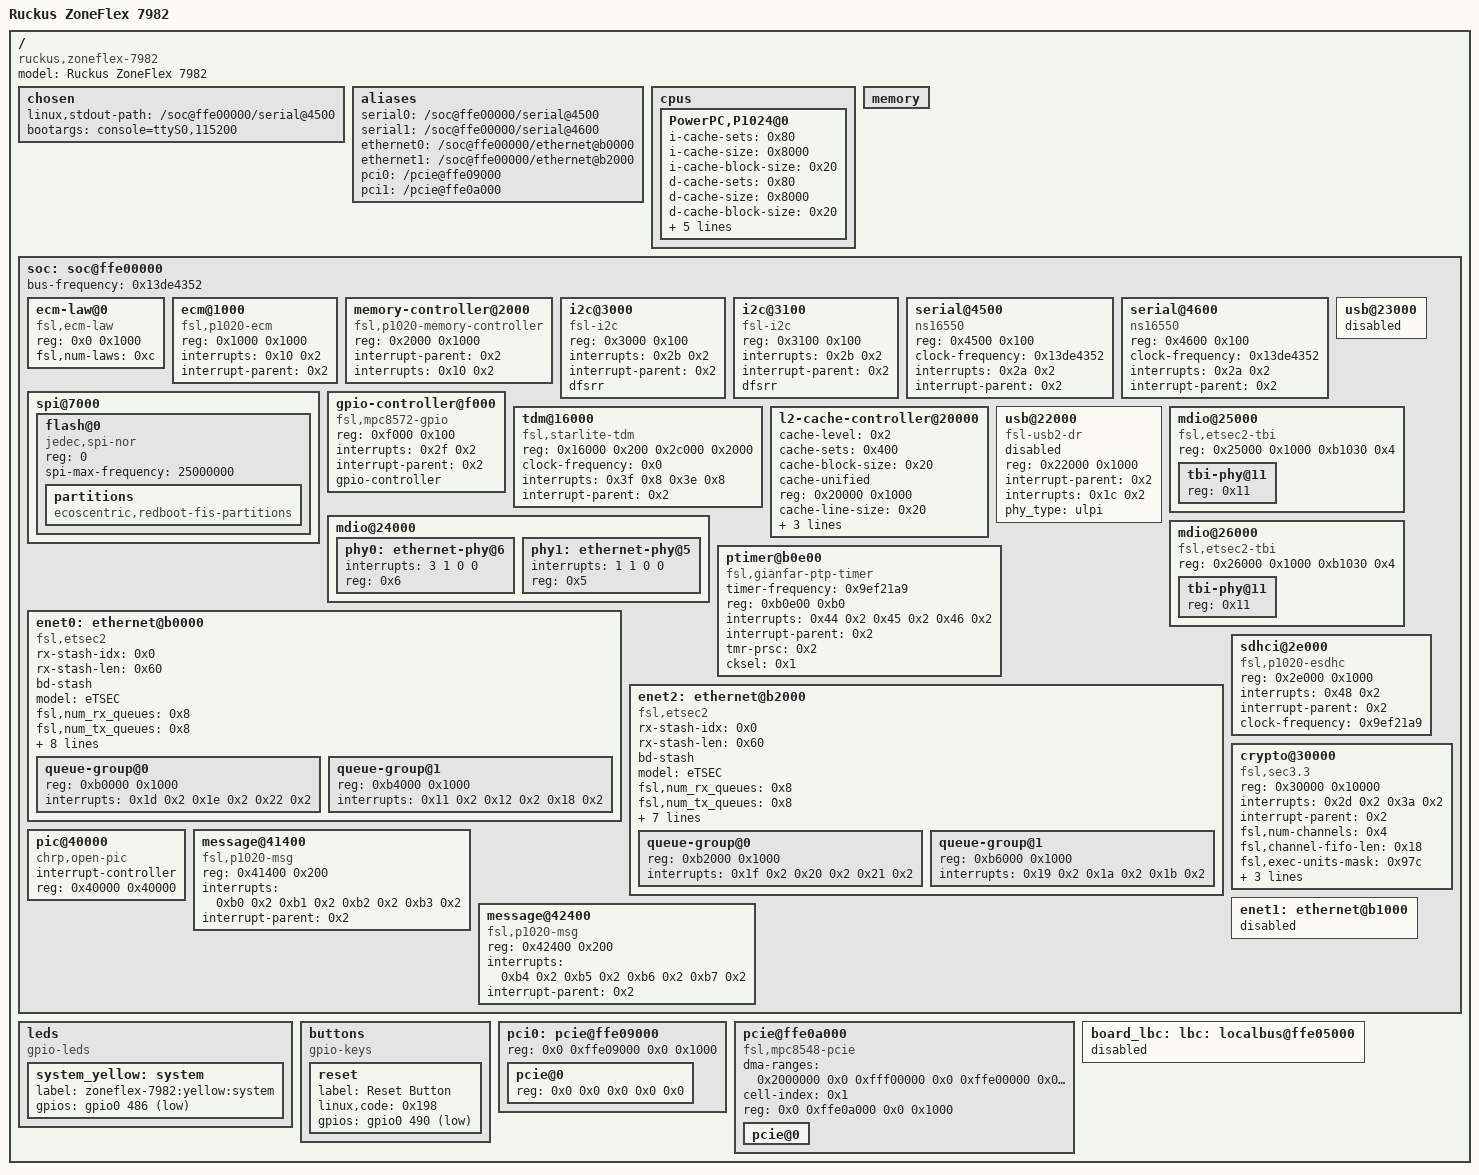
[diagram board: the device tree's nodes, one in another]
/dts-v1/;

/memreserve/	0x0000000007f00000 0x0000000000100000;
/memreserve/	0x0000000000ff6000 0x0000000000007000;
/ {
	model = "Ruckus ZoneFlex 7982";
	compatible = "ruckus,zoneflex-7982";
	#address-cells = <0x2>;
	#size-cells = <0x2>;

	chosen {
		linux,stdout-path = "/soc@ffe00000/serial@4500";
		bootargs = "console=ttyS0,115200";
	};

	aliases {
		serial0 = "/soc@ffe00000/serial@4500";
		serial1 = "/soc@ffe00000/serial@4600";
		ethernet0 = "/soc@ffe00000/ethernet@b0000";
		ethernet1 = "/soc@ffe00000/ethernet@b2000";
		pci0 = "/pcie@ffe09000";
		pci1 = "/pcie@ffe0a000";
	};

	cpus {
		#address-cells = <0x1>;
		#size-cells = <0x0>;

		PowerPC,P1024@0 {
			i-cache-sets = <0x80>;
			i-cache-size = <0x8000>;
			i-cache-block-size = <0x20>;
			d-cache-sets = <0x80>;
			d-cache-size = <0x8000>;
			d-cache-block-size = <0x20>;
			clock-frequency = <0x27bc86a4>;
			bus-frequency = <0x13de4352>;
			timebase-frequency = <0x27bc86a>;
			device_type = "cpu";
			reg = <0x0>;
			next-level-cache = <0x1>;
		};
	};

	memory {
		device_type = "memory";
	};

	soc: soc@ffe00000 {
		ranges = <0x0 0x0 0xffe00000 0x100000>;
		bus-frequency = <0x13de4352>;

		ecm-law@0 {
			compatible = "fsl,ecm-law";
			reg = <0x0 0x1000>;
			fsl,num-laws = <0xc>;
		};

		ecm@1000 {
			compatible = "fsl,p1020-ecm", "fsl,ecm";
			reg = <0x1000 0x1000>;
			interrupts = <0x10 0x2>;
			interrupt-parent = <0x2>;
		};

		memory-controller@2000 {
			compatible = "fsl,p1020-memory-controller";
			reg = <0x2000 0x1000>;
			interrupt-parent = <0x2>;
			interrupts = <0x10 0x2>;
		};

		i2c@3000 {
			#address-cells = <0x1>;
			#size-cells = <0x0>;
			compatible = "fsl-i2c";
			reg = <0x3000 0x100>;
			interrupts = <0x2b 0x2>;
			interrupt-parent = <0x2>;
			dfsrr;
		};

		i2c@3100 {
			#address-cells = <0x1>;
			#size-cells = <0x0>;
			compatible = "fsl-i2c";
			reg = <0x3100 0x100>;
			interrupts = <0x2b 0x2>;
			interrupt-parent = <0x2>;
			dfsrr;
		};

		serial@4500 {
			device_type = "serial";
			compatible = "ns16550";
			reg = <0x4500 0x100>;
			clock-frequency = <0x13de4352>;
			interrupts = <0x2a 0x2>;
			interrupt-parent = <0x2>;
		};

		serial@4600 {
			device_type = "serial";
			compatible = "ns16550";
			reg = <0x4600 0x100>;
			clock-frequency = <0x13de4352>;
			interrupts = <0x2a 0x2>;
			interrupt-parent = <0x2>;
		};

		spi@7000 {
			flash@0 {
				/* test with 40 mhz */
				compatible = "jedec,spi-nor";
				reg = <0>;
				spi-max-frequency = <25000000>;

				partitions {
					compatible = "ecoscentric,redboot-fis-partitions";
				};
			};
		};

		gpio-controller@f000 {
			#gpio-cells = <0x2>;
			compatible = "fsl,mpc8572-gpio";
			reg = <0xf000 0x100>;
			interrupts = <0x2f 0x2>;
			interrupt-parent = <0x2>;
			gpio-controller;
		};

		tdm@16000 {
			compatible = "fsl,starlite-tdm";
			reg = <0x16000 0x200 0x2c000 0x2000>;
			clock-frequency = <0x0>;
			interrupts = <0x3f 0x8 0x3e 0x8>;
			interrupt-parent = <0x2>;
		};

		l2-cache-controller@20000 {
			cache-level = <0x2>;
			cache-sets = <0x400>;
			cache-block-size = <0x20>;
			cache-unified;
			compatible = [66 73 6c 2c 70 31 30 31 31 2d 6c 32 2d 63 61 63 68 65 2d 63 6f 6e 74 72 6f 6c 6c 65 72 00 63 61 63 68 65 00 07 e7];
			reg = <0x20000 0x1000>;
			cache-line-size = <0x20>;
			cache-size = <0x40000>;
			interrupt-parent = <0x2>;
			interrupts = <0x10 0x2>;
			linux,phandle = <0x1>;
		};

		usb@22000 {
			status = "disabled";
		};

		usb@23000 {
			status = "disabled";
		};

		mdio@24000 {
			phy0: ethernet-phy@6 {
				interrupts = <3 1 0 0>;
				reg = <0x6>;
			};

			phy1: ethernet-phy@5 {
				/* todo check interupts. oem use cells: */
				interrupts = <1 1 0 0>;
				reg = <0x5>;
			};
		};

		mdio@25000 {
			#address-cells = <0x1>;
			#size-cells = <0x0>;
			compatible = "fsl,etsec2-tbi";
			reg = <0x25000 0x1000 0xb1030 0x4>;

			tbi-phy@11 {
				reg = <0x11>;
				device_type = "tbi-phy";
			};
		};

		mdio@26000 {
			#address-cells = <0x1>;
			#size-cells = <0x0>;
			compatible = "fsl,etsec2-tbi";
			reg = <0x26000 0x1000 0xb1030 0x4>;

			tbi-phy@11 {
				reg = <0x11>;
				device_type = "tbi-phy";
			};
		};

		ptimer@b0e00 {
			timer-frequency = <0x9ef21a9>;
			compatible = "fsl,gianfar-ptp-timer";
			reg = <0xb0e00 0xb0>;
			interrupts = <0x44 0x2 0x45 0x2 0x46 0x2>;
			interrupt-parent = <0x2>;
			tmr-prsc = <0x2>;
			cksel = <0x1>;
			linux,phandle = <0x4>;
		};

		ethernet@b0000 {
			rx-stash-idx = <0x0>;
			rx-stash-len = <0x60>;
			bd-stash;
			#address-cells = <0x1>;
			#size-cells = <0x1>;
			device_type = "network";
			model = "eTSEC";
			compatible = "fsl,etsec2";
			fsl,num_rx_queues = <0x8>;
			fsl,num_tx_queues = <0x8>;
			local-mac-address = [00 19 77 08 10 00];
			interrupt-parent = <0x2>;
			fixed-link = <0x1 0x1 0x3e8 0x0 0x0>;
			phy-handle = <0x3>;
			phy-connection-type = "rgmii-id";
			ptimer-handle = <0x4>;
			fsl,magic-packet;
			clk-handle = <0x5>;

			queue-group@0 {
				#address-cells = <0x1>;
				#size-cells = <0x1>;
				reg = <0xb0000 0x1000>;
				interrupts = <0x1d 0x2 0x1e 0x2 0x22 0x2>;
			};

			queue-group@1 {
				#address-cells = <0x1>;
				#size-cells = <0x1>;
				reg = <0xb4000 0x1000>;
				interrupts = <0x11 0x2 0x12 0x2 0x18 0x2>;
			};
		};

		ethernet@b2000 {
			rx-stash-idx = <0x0>;
			rx-stash-len = <0x60>;
			bd-stash;
			#address-cells = <0x1>;
			#size-cells = <0x1>;
			device_type = "network";
			model = "eTSEC";
			compatible = "fsl,etsec2";
			fsl,num_rx_queues = <0x8>;
			fsl,num_tx_queues = <0x8>;
			local-mac-address = [00 19 77 08 10 01];
			interrupt-parent = <0x2>;
			phy-handle = <0x6>;
			phy-connection-type = "rgmii-id";
			ptimer-handle = <0x4>;
			fsl,magic-packet;
			clk-handle = <0x7>;

			queue-group@0 {
				#address-cells = <0x1>;
				#size-cells = <0x1>;
				reg = <0xb2000 0x1000>;
				interrupts = <0x1f 0x2 0x20 0x2 0x21 0x2>;
			};

			queue-group@1 {
				#address-cells = <0x1>;
				#size-cells = <0x1>;
				reg = <0xb6000 0x1000>;
				interrupts = <0x19 0x2 0x1a 0x2 0x1b 0x2>;
			};
		};

		usb@22000 {
			#address-cells = <0x1>;
			#size-cells = <0x0>;
			compatible = "fsl-usb2-dr";
			reg = <0x22000 0x1000>;
			interrupt-parent = <0x2>;
			interrupts = <0x1c 0x2>;
			phy_type = "ulpi";
		};

		sdhci@2e000 {
			status = "okay";
			compatible = "fsl,p1020-esdhc", "fsl,esdhc";
			reg = <0x2e000 0x1000>;
			interrupts = <0x48 0x2>;
			interrupt-parent = <0x2>;
			clock-frequency = <0x9ef21a9>;
		};

		crypto@30000 {
			compatible = "fsl,sec3.3", "fsl,sec3.1", "fsl,sec3.0", "fsl,sec2.4", "fsl,sec2.2", "fsl,sec2.1", "fsl,sec2.0";
			reg = <0x30000 0x10000>;
			interrupts = <0x2d 0x2 0x3a 0x2>;
			interrupt-parent = <0x2>;
			fsl,num-channels = <0x4>;
			fsl,channel-fifo-len = <0x18>;
			fsl,exec-units-mask = <0x97c>;
			fsl,descriptor-types-mask = <0x3a30abf>;
			fsl,multi-host-mode = "primary";
			fsl,channel-remap = <0x3>;
		};

		pic@40000 {
			interrupt-controller;
			#address-cells = <0x0>;
			#interrupt-cells = <0x2>;
			reg = <0x40000 0x40000>;
			compatible = "chrp,open-pic";
			device_type = "open-pic";
			linux,phandle = <0x2>;
		};

		message@41400 {
			compatible = "fsl,p1020-msg", "fsl,mpic-msg";
			reg = <0x41400 0x200>;
			interrupts = <0xb0 0x2 0xb1 0x2 0xb2 0x2 0xb3 0x2>;
			interrupt-parent = <0x2>;
		};

		message@42400 {
			compatible = "fsl,p1020-msg", "fsl,mpic-msg";
			reg = <0x42400 0x200>;
			interrupts = <0xb4 0x2 0xb5 0x2 0xb6 0x2 0xb7 0x2>;
			interrupt-parent = <0x2>;
		};

		enet0: ethernet@b0000 {
			status = "okay";
			phy-handle = <&phy0>;
			phy-connection-type = "rgmii-id";
		};

		enet1: ethernet@b1000 {
			status = "disabled";
		};

		enet2: ethernet@b2000 {
			status = "okay";
			phy-handle = <&phy1>;
			phy-connection-type = "rgmii-id";
		};
	};

	leds {
		compatible = "gpio-leds";

		system_yellow: system {
			label = "zoneflex-7982:yellow:system";
			gpios = <&gpio0 486 1>;
		};
/*
		system_red {
			label = "zoneflex-7982:red:system";
			gpios = <&gpio0 489 1>;
		};
*/
	};

	buttons {
		compatible = "gpio-keys";

		reset {
			label = "Reset Button";
			linux,code = <0x198>;
			gpios = <&gpio0 490 1>;
		};
	};

	pci0: pcie@ffe09000 {
		reg = <0x0 0xffe09000 0x0 0x1000>;
		ranges = <0x2000000 0x0 0xa0000000 0x0 0xa0000000 0x0 0x20000000
			0x1000000 0x0 0x00000000 0x0 0xffc30000 0x0 0x10000>;
		pcie@0 {
			reg = <0x0 0x0 0x0 0x0 0x0>;
			#size-cells = <0x2>;
			#address-cells = <0x3>;
			device_type = "pci";
			ranges = <0x2000000 0x0 0xa0000000 0x2000000 0x0 0xa0000000 0x0 0x20000000 0x1000000 0x0 0x0 0x1000000 0x0 0x0 0x0 0x100000>;
		};
	};

	pcie@ffe0a000 {
		dma-ranges = <0x2000000 0x0 0xfff00000 0x0 0xffe00000 0x0 0x100000 0x42000000 0x0 0x0 0x0 0x0 0x0 0x8000000>;
		compatible = "fsl,mpc8548-pcie";
		cell-index = <0x1>;
		device_type = "pci";
		#interrupt-cells = <0x1>;
		#size-cells = <0x2>;
		#address-cells = <0x3>;
		reg = <0x0 0xffe0a000 0x0 0x1000>;
		ranges = <0x2000000 0x0 0xc0000000 0x0 0xc0000000 0x0 0x20000000
		      0x1000000 0x0 0x00000000 0x0 0xffc20000 0x0 0x10000>;
		pcie@0 {
			ranges = <0x2000000 0x0 0xc0000000
			      0x2000000 0x0 0xc0000000
				  0x0 0x20000000

				  0x1000000 0x0 0x0
				  0x1000000 0x0 0x0
				  0x0 0x100000>;
		};
	};

	board_lbc: lbc: localbus@ffe05000 {
		status = "disabled";
	};

};
